# STM32U599xx register map
File version: 1.0
Registers are 32-bit, read-write, reset 0x0 unless marked. A register's access mark holds for its fields unless they carry their own. Offsets are from the block's base; [hi:lo] are bit positions; lines under a group give offsets from that group; {n}, {i} and the like mark numbered series.

## TSC — Touch Sensing Controller (TSC)
Base 0x40024000
Same registers: TSC_S 0x50024000
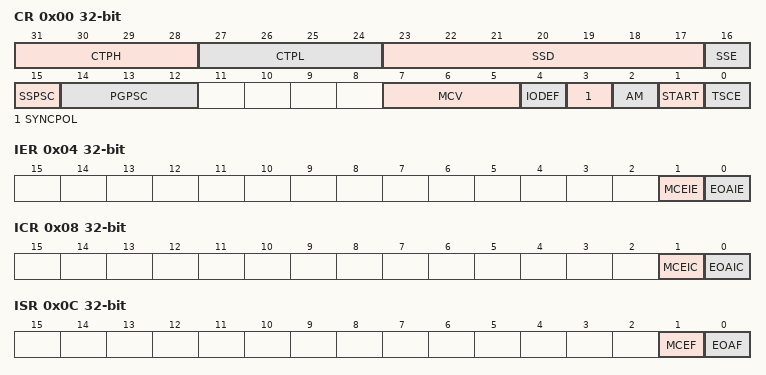
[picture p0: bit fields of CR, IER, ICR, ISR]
0x00 CR — TSC control register
  [31:28] CTPH — CTPH[3:0] bits (Charge Transfer pulse high)
  [27:24] CTPL — CTPL[3:0] bits (Charge Transfer pulse low)
  [23:17] SSD — SSD[6:0] bits (Spread Spectrum Deviation)
  [16] SSE — Spread Spectrum Enable
  [15] SSPSC — Spread Spectrum Prescaler
  [14:12] PGPSC — PGPSC[2:0] bits (Pulse Generator Prescaler)
  [7:5] MCV — MCV[2:0] bits (Max Count Value)
  [4] IODEF — IO default mode
  [3] SYNCPOL — Synchronization pin polarity
  [2] AM — Acquisition mode
  [1] START — Start acquisition
  [0] TSCE — Touch sensing controller enable
0x04 IER — TSC interrupt enable register
  [1] MCEIE — Max count error interrupt enable
  [0] EOAIE — End of acquisition interrupt enable
0x08 ICR — TSC interrupt clear register
  [1] MCEIC — Max count error interrupt clear
  [0] EOAIC — End of acquisition interrupt clear
0x0C ISR — TSC interrupt status register
  [1] MCEF — Max count error flag
  [0] EOAF — End of acquisition flag
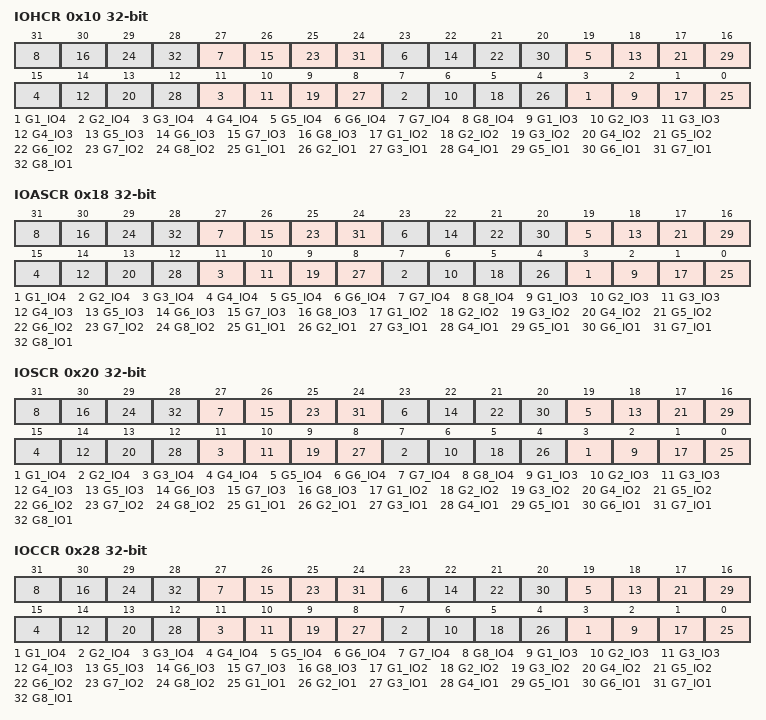
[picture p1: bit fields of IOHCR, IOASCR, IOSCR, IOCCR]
0x10 IOHCR — TSC I/O hysteresis control register
  [4n-1] G{n}_IO4 (n=1..8) — GROUP{n}_IO4 schmitt trigger hysteresis mode
  [4n-2] G{n}_IO3 (n=1..8) — GROUP{n}_IO3 schmitt trigger hysteresis mode
  [4n-3] G{n}_IO2 (n=1..8) — GROUP{n}_IO2 schmitt trigger hysteresis mode
  [4n-4] G{n}_IO1 (n=1..8) — GROUP{n}_IO1 schmitt trigger hysteresis mode
0x18 IOASCR — TSC I/O analog switch control register
  [4n-1] G{n}_IO4 (n=1..8) — GROUP{n}_IO4 analog switch enable
  [4n-2] G{n}_IO3 (n=1..8) — GROUP{n}_IO3 analog switch enable
  [4n-3] G{n}_IO2 (n=1..8) — GROUP{n}_IO2 analog switch enable
  [4n-4] G{n}_IO1 (n=1..8) — GROUP{n}_IO1 analog switch enable
0x20 IOSCR — TSC I/O sampling control register
  [4n-1] G{n}_IO4 (n=1..8) — GROUP{n}_IO4 sampling mode
  [4n-2] G{n}_IO3 (n=1..8) — GROUP{n}_IO3 sampling mode
  [4n-3] G{n}_IO2 (n=1..8) — GROUP{n}_IO2 sampling mode
  [4n-4] G{n}_IO1 (n=1..8) — GROUP{n}_IO1 sampling mode
0x28 IOCCR — TSC I/O channel control register
  [4n-1] G{n}_IO4 (n=1..8) — GROUP{n}_IO4 channel mode
  [4n-2] G{n}_IO3 (n=1..8) — GROUP{n}_IO3 channel mode
  [4n-3] G{n}_IO2 (n=1..8) — GROUP{n}_IO2 channel mode
  [4n-4] G{n}_IO1 (n=1..8) — GROUP{n}_IO1 channel mode
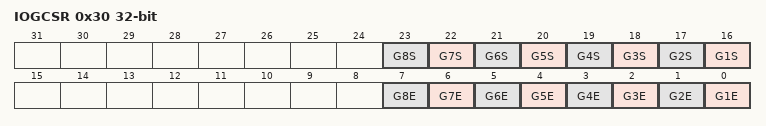
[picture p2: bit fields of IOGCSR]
0x30 IOGCSR — TSC I/O group control status register
  [n+15] G{n}S (n=1..8) — Analog IO GROUP{n} status
  [n-1] G{n}E (n=1..8) — Analog IO GROUP{n} enable
{0x30+4i} IOG{i}CR (i=1..8) — TSC I/O group x counter register
  [13:0] CNT — CNT[13:0] bits (Counter value)

## RAMCFG_BKPRAM — SRAMs configuration controller
Base 0x40026100
Same registers: RAMCFG_BKPRAM_S 0x50026100
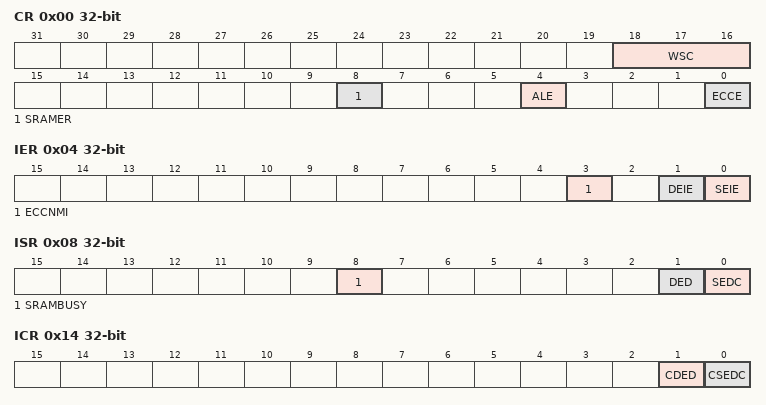
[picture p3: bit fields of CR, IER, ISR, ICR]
0x00 CR — Control Register
  [18:16] WSC — WSC[18:16] Wait State Configuration field
  [8] SRAMER — Start Erase
  [4] ALE — Address Latching Enable
  [0] ECCE — ECC Enable
0x04 IER — Interrupt Enable Register
  [3] ECCNMI — NMI redirection interrupt
  [1] DEIE — Double Error Interrupt Enable
  [0] SEIE — Single Error Interrupt Enable
0x08 ISR — Interrupt Status Register
  [8] SRAMBUSY — SRAM busy flag
  [1] DED — Double Error Detected flag
  [0] SEDC — Single Error Detected and Corrected flag
0x0C SEAR — ECC Single Error Address Register
  [31:0] ESEA — ECC Single Error Address
0x10 DEAR — ECC Double Error Address Register
  [31:0] EDEA — ECC Double Error Address
0x14 ICR — Interrupt Clear Register
  [1] CDED — Clear ECC Double Error Detected Flag
  [0] CSEDC — Clear ECC Single Error Detected and Corrected Flag
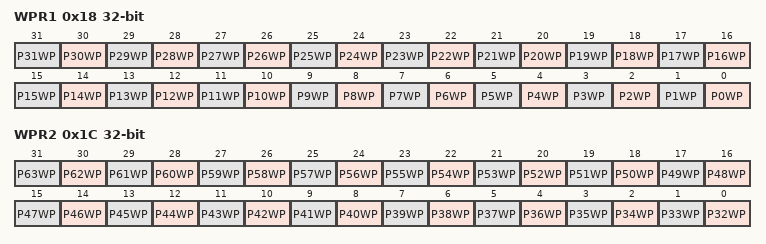
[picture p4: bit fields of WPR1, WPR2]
0x18 WPR1 — SRAM Write Protection Register 1
  [n] P{n}WP (n=0..31) — Write Protection Page {n:02}
0x1C WPR2 — SRAM Write Protection Register 2
  [n-32] P{n}WP (n=32..63) — Write Protection Page {n}
0x24 ECCKEY — SRAM ECC Key Register
0x28 ERKEYR — SRAM Erase Key Register
  [7:0] ERASEKEY — Erase Write Protection Key
